# Template register map
Vendor: VendorName Co.Ltd; Series: SeriesName; File version: 1.2
CPU: CM7 r0p1, little endian, MPU, FPU, 4 interrupt priority bits
Registers are 32-bit, read-write, no defined reset value unless marked. A register's access mark holds for its fields unless they carry their own. Offsets are from the block's base; [hi:lo] are bit positions; lines under a group give offsets from that group; {n}, {i} and the like mark numbered series.

## ANASS — Analog Subsystem
Base 0x40034000
0x00 CONFIGLOCK — ANASS config locker register
  [3] AGPIOCTRL — ANASS AGPIOCTRL bit: lock all register of AGPIOCTRL
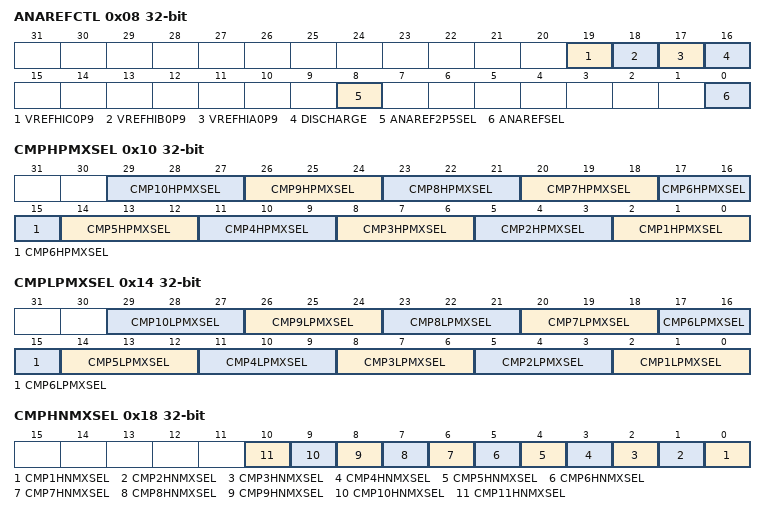
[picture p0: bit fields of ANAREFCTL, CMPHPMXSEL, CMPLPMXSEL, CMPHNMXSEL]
0x08 ANAREFCTL — ANASS vref control register
  [19] VREFHIC0P9 — ANASS VREFHIC0P9 bit: VREFHIC 0.9 times partial voltage enable
  [18] VREFHIB0P9 — ANASS VREFHIB0P9 bit: VREFHIB 0.9 times partial voltage enable
  [17] VREFHIA0P9 — ANASS VREFHIA0P9 bit: VREFHIA 0.9 times partial voltage enable
  [16] DISCHARGE — ANASS DISCHARGE bit: VRBUF electric discharge enable bit
  [8] ANAREF2P5SEL — ANASS ANAREF2P5SEL bit: analog reference voltage gear selection
  [0] ANAREFSEL — ANASS ANAREFSEL bit: analog reference mode selection
0x10 CMPHPMXSEL — ANASS comparer HP selection register
  [3n-1:3n-3] CMP{n}HPMXSEL (n=1..10) — ANASS CMP{n}HPMXSEL[2:0] bit: comparator {n} subsystem high comparator positive select
0x14 CMPLPMXSEL — ANASS comparer LP selection register
  [3n-1:3n-3] CMP{n}LPMXSEL (n=1..10) — ANASS CMP{n}LPMXSEL[2:0] bit: comparator {n} subsystem low comparator positive select
0x18 CMPHNMXSEL — ANASS comparer HN selection register
  [n-1] CMP{n}HNMXSEL (n=1..11) — ANASS CMP{n}HNMXSEL bit: comparator {n} subsystem high comparator negative select
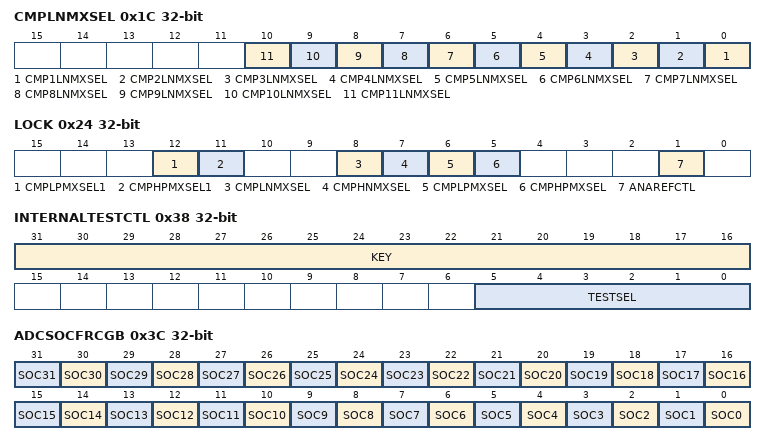
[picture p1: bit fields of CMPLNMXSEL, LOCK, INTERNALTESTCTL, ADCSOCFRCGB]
0x1C CMPLNMXSEL — ANASS comparer LN selection register
  [n-1] CMP{n}LNMXSEL (n=1..11) — ANASS CMP{n}LNMXSEL bit: comparator {n} subsystem low comparator negative select
0x24 LOCK — ANASS locker register
  [12] CMPLPMXSEL1 — ANASS CMPLPMXSEL1 bit: CMPLPMXSEL1 register lock bit
  [11] CMPHPMXSEL1 — ANASS CMPHPMXSEL1 bit: CMPHPMXSEL1 register lock bit
  [8] CMPLNMXSEL — ANASS CMPLNMXSEL bit: CMPLNMXSEL register lock bit
  [7] CMPHNMXSEL — ANASS CMPHNMXSEL bit: CMPHNMXSEL register lock bit
  [6] CMPLPMXSEL — ANASS CMPLPMXSEL bit: CMPLPMXSEL register lock bit
  [5] CMPHPMXSEL — ANASS CMPHPMXSEL bit: CMPHPMXSEL register lock bit
  [1] ANAREFCTL — ANASS ANAREFCTL bit: ANAREFCTL register lock bit
0x30 CMPHPMXSEL1 — ANASS comparer HP selection register 1
  [2:0] CMP11HPMXSEL — ANASS CMP11HPMXSEL[2:0] bit: comparator 11 subsystem high comparator positive select
0x34 CMPLPMXSEL1 — ANASS comparer LP selection register 1
  [2:0] CMP11LPMXSEL — ANASS CMP11LPMXSEL[2:0] bit: comparator 11 subsystem low comparator positive select
0x38 INTERNALTESTCTL — ANASS inner test node control register
  [31:16] KEY wo — ANASS KEY[15:0] bit: only when 0xA5A5 is written at the high position can this register be written
  [5:0] TESTSEL — ANASS TESTSEL[5:0] bit: text selection
0x3C ADCSOCFRCGB — ANASS ADC SOC config register
  [n] SOC{n} (n=0..31) — ANASS SOC{n} bit: whether choose SOC{n} to global software trigger
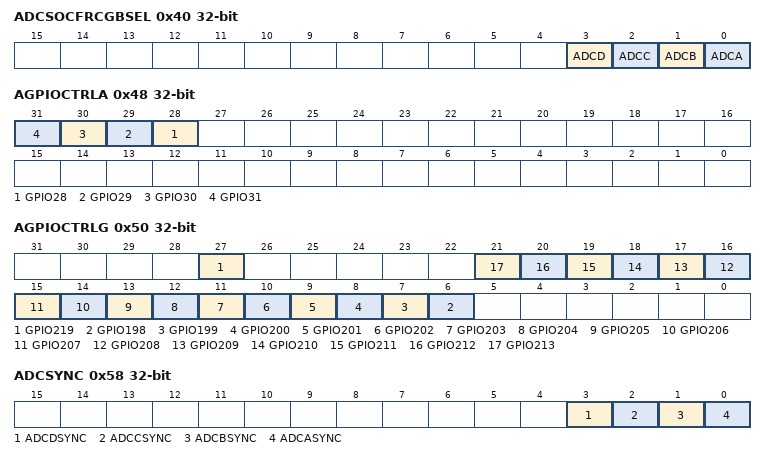
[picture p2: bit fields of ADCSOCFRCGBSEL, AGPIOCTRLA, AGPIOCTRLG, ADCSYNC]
0x40 ADCSOCFRCGBSEL — ANASS ADC config register
  [3] ADCD — ANASS ADCD bit: whether choose ADCD to global software trigger
  [2] ADCC — ANASS ADCC bit: whether choose ADCC to global software trigger
  [1] ADCB — ANASS ADCB bit: whether choose ADCB to global software trigger
  [0] ADCA — ANASS ADCA bit: whether choose ADCA to global software trigger
0x48 AGPIOCTRLA — ANASS AGPIO control in GPIOA group register
  [n] GPIO{n} (n=28..31) — ANASS GPIO{n} bit: configure GPIO{n} to determine whether to enable the AGPIO function
0x4C AGPIOCTRLB — ANASS AGPIO control in GPIOB group register
  [0] GPIO32 — ANASS GPIO32 bit: configure GPIO32 to determine whether to enable the AGPIO function
0x50 AGPIOCTRLG — ANASS AGPIO control in GPIOG group register
  [27] GPIO219 — ANASS GPIO219 bit: configure GPIO219 to determine whether to enable the AGPIO function
  [n-192] GPIO{n} (n=198..213) — ANASS GPIO{n} bit: configure GPIO{n} to determine whether to enable the AGPIO function
0x58 ADCSYNC — ANASS ADC synchronous control register
  [3] ADCDSYNC — ANASS ADCDSYNC bit: ADCD clock frequency division and phase synchronization
  [2] ADCCSYNC — ANASS ADCCSYNC bit: ADCC clock frequency division and phase synchronization
  [1] ADCBSYNC — ANASS ADCBSYNC bit: ADCB clock frequency division and phase synchronization
  [0] ADCASYNC — ANASS ADCASYNC bit: ADCA clock frequency division and phase synchronization
